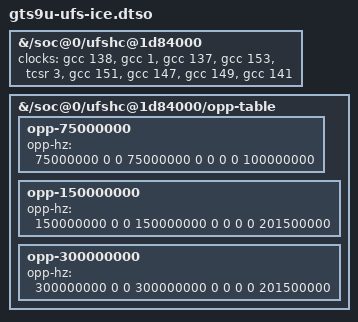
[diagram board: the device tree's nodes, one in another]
// SPDX-License-Identifier: BSD-3-Clause
/dts-v1/;
/plugin/;

/*
 * Applied by Linux before the UFS host probes, never by Samsung ABL, and
 * apart from gts9u-performance.dtso so that neither can cost the other.
 *
 * The UFS inline crypto engine sits in the data path of every UFS transfer,
 * encrypted or not, and the bootloader leaves its core clock on XO.  At
 * 19.2 MHz it caps all UFS I/O near 300 MB/s.  These fragments list the
 * clock with the controller's own, so the UFS OPPs scale it.
 *
 * The rates are corners of Samsung's gcc-kalama.c: 100 MHz at VDD_LOWER and
 * 201.5 MHz at VDD_LOW.  Its third corner, 403 MHz at VDD_NOMINAL, is left
 * out.  On this tablet's HS-G4 link it measured the same as 201.5 MHz at
 * every queue depth (docs/performance-2.1.0.md), and it is the one rate that
 * would lean on CX being held at its maximum, which nothing here votes for.
 * A build that brings the link up in HS-G5 has to revisit that.
 *
 * No preprocessor runs on this file, so the clock IDs are numbers: those of
 * dt-bindings/clock/qcom,sm8550-gcc.h and qcom,sm8550-tcsr.h.
 */
/ {
	fragment@0 {
		target-path = "/soc@0/ufshc@1d84000";
		__overlay__ {
			clocks = <&gcc 138>,	/* GCC_UFS_PHY_AXI_CLK */
				 <&gcc 1>,	/* GCC_AGGRE_UFS_PHY_AXI_CLK */
				 <&gcc 137>,	/* GCC_UFS_PHY_AHB_CLK */
				 <&gcc 153>,	/* GCC_UFS_PHY_UNIPRO_CORE_CLK */
				 <&tcsr 3>,	/* TCSR_UFS_PAD_CLKREF_EN */
				 <&gcc 151>,	/* GCC_UFS_PHY_TX_SYMBOL_0_CLK */
				 <&gcc 147>,	/* GCC_UFS_PHY_RX_SYMBOL_0_CLK */
				 <&gcc 149>,	/* GCC_UFS_PHY_RX_SYMBOL_1_CLK */
				 <&gcc 141>;	/* GCC_UFS_PHY_ICE_CORE_CLK */
			clock-names = "core_clk",
				      "bus_aggr_clk",
				      "iface_clk",
				      "core_clk_unipro",
				      "ref_clk",
				      "tx_lane0_sync_clk",
				      "rx_lane0_sync_clk",
				      "rx_lane1_sync_clk",
				      "ice_core_clk";
		};
	};

	fragment@1 {
		target-path = "/soc@0/ufshc@1d84000/opp-table";
		__overlay__ {
			opp-75000000 {
				opp-hz = /bits/ 64 <75000000 0 0 75000000 0 0 0 0
						    100000000>;
			};

			opp-150000000 {
				opp-hz = /bits/ 64 <150000000 0 0 150000000 0 0 0 0
						    201500000>;
			};

			opp-300000000 {
				opp-hz = /bits/ 64 <300000000 0 0 300000000 0 0 0 0
						    201500000>;
			};
		};
	};
};
